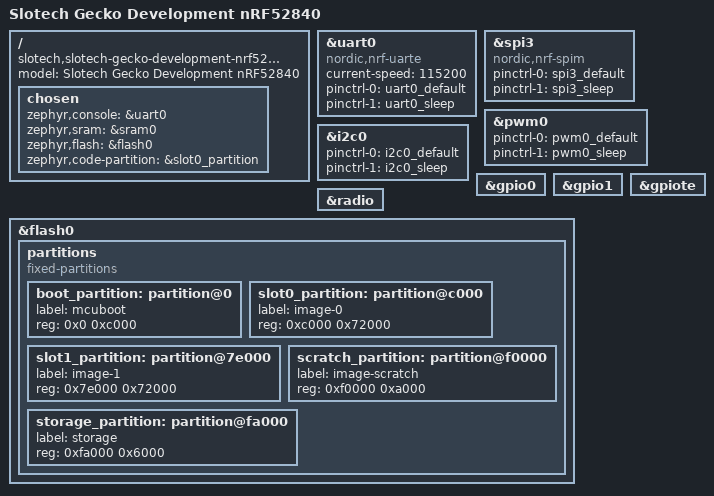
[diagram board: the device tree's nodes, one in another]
// Copyright (c) 2024 Nordic Semiconductor ASA
// SPDX-License-Identifier: Apache-2.0

/dts-v1/;
#include <nordic/nrf52840_qfaa.dtsi>
#include "slotech_gecko_development_nrf52840-pinctrl.dtsi"

/ {
	model = "Slotech Gecko Development nRF52840";
	compatible = "slotech,slotech-gecko-development-nrf52840";

	chosen {
		zephyr,console = &uart0;
		zephyr,sram = &sram0;
		zephyr,flash = &flash0;
		zephyr,code-partition = &slot0_partition;
	};
};

&uart0 {
	compatible = "nordic,nrf-uarte";
	status = "okay";
	current-speed = <115200>;
	// hw-flow-control;
	pinctrl-0 = <&uart0_default>;
	pinctrl-1 = <&uart0_sleep>;
	pinctrl-names = "default", "sleep";
};

&spi3 {
	compatible = "nordic,nrf-spim";
	status = "okay";
	pinctrl-0 = <&spi3_default>;
	pinctrl-1 = <&spi3_sleep>;
	pinctrl-names = "default", "sleep";
};

&pwm0 {
	status = "okay";
	pinctrl-0 = <&pwm0_default>;
	pinctrl-1 = <&pwm0_sleep>;
	pinctrl-names = "default", "sleep";
};

&i2c0 {
	status = "okay";
	pinctrl-0 = <&i2c0_default>;
	pinctrl-1 = <&i2c0_sleep>;
	pinctrl-names = "default", "sleep";
};

&gpio0 {
	status = "okay";
};

&gpio1 {
	status = "okay";
};

&gpiote {
    status = "okay";
};

&radio {
	status = "okay";
};

&flash0 {
	partitions {
		compatible = "fixed-partitions";
		#address-cells = <1>;
		#size-cells = <1>;

		boot_partition: partition@0 {
			label = "mcuboot";
			reg = <0x0 0xc000>;
		};
		slot0_partition: partition@c000 {
			label = "image-0";
			reg = <0xc000 0x72000>;
		};
		slot1_partition: partition@7e000 {
			label = "image-1";
			reg = <0x7e000 0x72000>;
		};
		scratch_partition: partition@f0000 {
			label = "image-scratch";
			reg = <0xf0000 0xa000>;
		};
		storage_partition: partition@fa000 {
			label = "storage";
			reg = <0xfa000 0x6000>;
		};
	};
};

